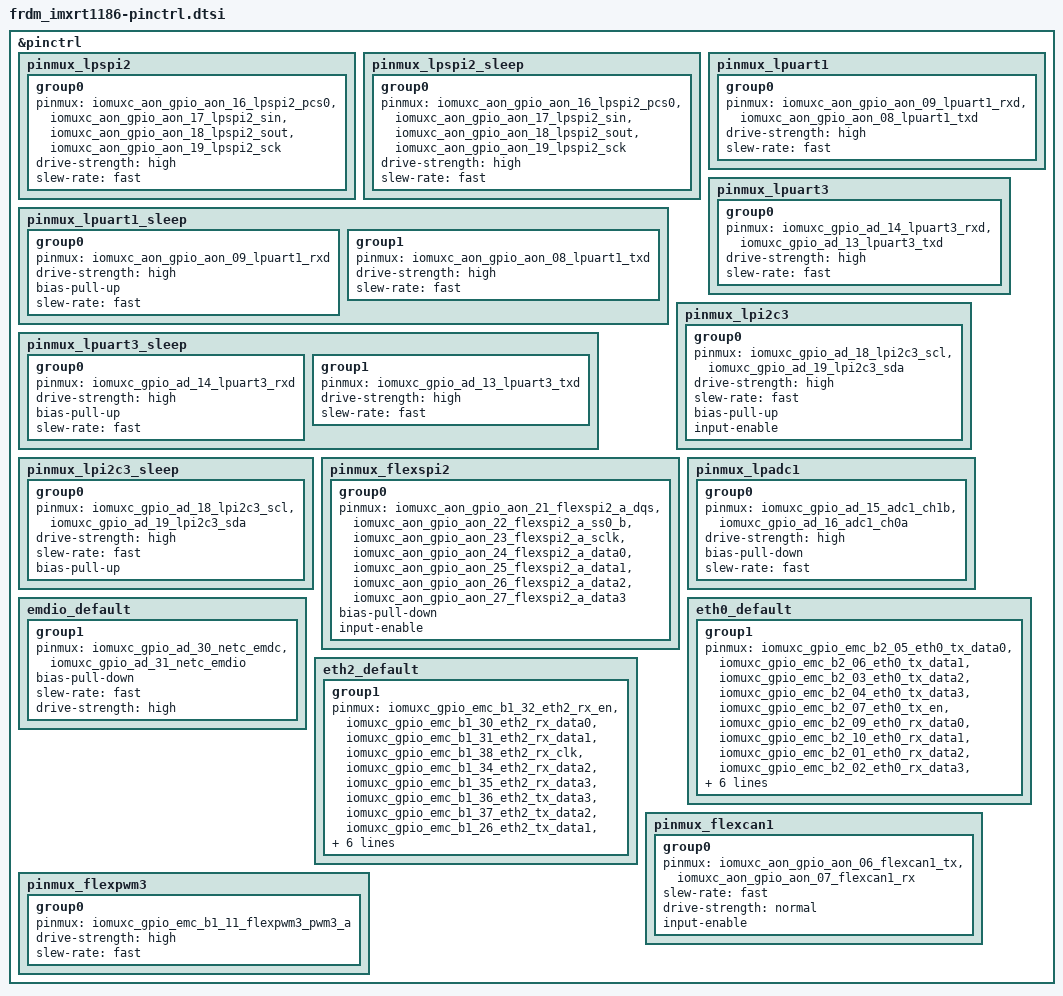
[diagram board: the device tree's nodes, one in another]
/*
 * Copyright 2026 NXP
 * SPDX-License-Identifier: Apache-2.0
 *
 */

#include <nxp/nxp_imx/rt/mimxrt1186cvj8c-pinctrl.dtsi>

&pinctrl {
	pinmux_lpspi2: pinmux_lpspi2 {
		group0 {
			pinmux = <&iomuxc_aon_gpio_aon_16_lpspi2_pcs0>,
				 <&iomuxc_aon_gpio_aon_17_lpspi2_sin>,
				 <&iomuxc_aon_gpio_aon_18_lpspi2_sout>,
				 <&iomuxc_aon_gpio_aon_19_lpspi2_sck>;
			drive-strength = "high";
			slew-rate = "fast";
		};
	};

	pinmux_lpspi2_sleep: pinmux_lpspi2_sleep {
		group0 {
			pinmux = <&iomuxc_aon_gpio_aon_16_lpspi2_pcs0>,
				 <&iomuxc_aon_gpio_aon_17_lpspi2_sin>,
				 <&iomuxc_aon_gpio_aon_18_lpspi2_sout>,
				 <&iomuxc_aon_gpio_aon_19_lpspi2_sck>;
			drive-strength = "high";
			slew-rate = "fast";
		};
	};

	pinmux_lpuart1: pinmux_lpuart1 {
		group0 {
			pinmux = <&iomuxc_aon_gpio_aon_09_lpuart1_rxd>,
				 <&iomuxc_aon_gpio_aon_08_lpuart1_txd>;
			drive-strength = "high";
			slew-rate = "fast";
		};
	};

	pinmux_lpuart1_sleep: pinmux_lpuart1_sleep {
		group0 {
			pinmux = <&iomuxc_aon_gpio_aon_09_lpuart1_rxd>;
			drive-strength = "high";
			bias-pull-up;
			slew-rate = "fast";
		};

		group1 {
			pinmux = <&iomuxc_aon_gpio_aon_08_lpuart1_txd>;
			drive-strength = "high";
			slew-rate = "fast";
		};
	};

	pinmux_lpuart3: pinmux_lpuart3 {
		group0 {
			pinmux = <&iomuxc_gpio_ad_14_lpuart3_rxd>,
				 <&iomuxc_gpio_ad_13_lpuart3_txd>;
			drive-strength = "high";
			slew-rate = "fast";
		};
	};

	pinmux_lpuart3_sleep: pinmux_lpuart3_sleep {
		group0 {
			pinmux = <&iomuxc_gpio_ad_14_lpuart3_rxd>;
			drive-strength = "high";
			bias-pull-up;
			slew-rate = "fast";
		};

		group1 {
			pinmux = <&iomuxc_gpio_ad_13_lpuart3_txd>;
			drive-strength = "high";
			slew-rate = "fast";
		};
	};

	pinmux_lpi2c3: pinmux_lpi2c3 {
		group0 {
			pinmux = <&iomuxc_gpio_ad_18_lpi2c3_scl>,
				 <&iomuxc_gpio_ad_19_lpi2c3_sda>;
			drive-strength = "high";
			slew-rate = "fast";
			bias-pull-up;
			input-enable;
		};
	};

	pinmux_lpi2c3_sleep: pinmux_lpi2c3_sleep {
		group0 {
			pinmux = <&iomuxc_gpio_ad_18_lpi2c3_scl>,
				 <&iomuxc_gpio_ad_19_lpi2c3_sda>;
			drive-strength = "high";
			slew-rate = "fast";
			bias-pull-up;
		};
	};

	/* QSPI Flash on FlexSPI2 - GPIO_AON_22/23/24/25/26/27 */
	pinmux_flexspi2: pinmux_flexspi2 {
		group0 {
			pinmux = <&iomuxc_aon_gpio_aon_21_flexspi2_a_dqs>,
				 <&iomuxc_aon_gpio_aon_22_flexspi2_a_ss0_b>,
				 <&iomuxc_aon_gpio_aon_23_flexspi2_a_sclk>,
				 <&iomuxc_aon_gpio_aon_24_flexspi2_a_data0>,
				 <&iomuxc_aon_gpio_aon_25_flexspi2_a_data1>,
				 <&iomuxc_aon_gpio_aon_26_flexspi2_a_data2>,
				 <&iomuxc_aon_gpio_aon_27_flexspi2_a_data3>;
			bias-pull-down;
			input-enable;
		};
	};

	pinmux_lpadc1: pinmux_lpadc1 {
		group0 {
			pinmux = <&iomuxc_gpio_ad_15_adc1_ch1b>,
				 <&iomuxc_gpio_ad_16_adc1_ch0a>;
			drive-strength = "high";
			bias-pull-down;
			slew-rate = "fast";
		};
	};

	emdio_default: emdio_default {
		group1 {
			pinmux = <&iomuxc_gpio_ad_30_netc_emdc>,
				 <&iomuxc_gpio_ad_31_netc_emdio>;
			bias-pull-down;
			slew-rate = "fast";
			drive-strength = "high";
		};
	};

	eth0_default: eth0_default {
		group1 {
			pinmux = <&iomuxc_gpio_emc_b2_05_eth0_tx_data0>,
				 <&iomuxc_gpio_emc_b2_06_eth0_tx_data1>,
				 <&iomuxc_gpio_emc_b2_03_eth0_tx_data2>,
				 <&iomuxc_gpio_emc_b2_04_eth0_tx_data3>,
				 <&iomuxc_gpio_emc_b2_07_eth0_tx_en>,
				 <&iomuxc_gpio_emc_b2_09_eth0_rx_data0>,
				 <&iomuxc_gpio_emc_b2_10_eth0_rx_data1>,
				 <&iomuxc_gpio_emc_b2_01_eth0_rx_data2>,
				 <&iomuxc_gpio_emc_b2_02_eth0_rx_data3>,
				 <&iomuxc_gpio_emc_b2_11_eth0_rx_en>,
				 <&iomuxc_gpio_emc_b2_08_eth0_tx_clk>,
				 <&iomuxc_gpio_emc_b2_00_eth0_rx_clk>;
			bias-pull-down;
			slew-rate = "fast";
			drive-strength = "high";
		};
	};

	eth2_default: eth2_default {
		group1 {
			pinmux = <&iomuxc_gpio_emc_b1_32_eth2_rx_en>,
				 <&iomuxc_gpio_emc_b1_30_eth2_rx_data0>,
				 <&iomuxc_gpio_emc_b1_31_eth2_rx_data1>,
				 <&iomuxc_gpio_emc_b1_38_eth2_rx_clk>,
				 <&iomuxc_gpio_emc_b1_34_eth2_rx_data2>,
				 <&iomuxc_gpio_emc_b1_35_eth2_rx_data3>,
				 <&iomuxc_gpio_emc_b1_36_eth2_tx_data3>,
				 <&iomuxc_gpio_emc_b1_37_eth2_tx_data2>,
				 <&iomuxc_gpio_emc_b1_26_eth2_tx_data1>,
				 <&iomuxc_gpio_emc_b1_27_eth2_tx_data0>,
				 <&iomuxc_gpio_emc_b1_28_eth2_tx_en>,
				 <&iomuxc_gpio_emc_b1_29_eth2_tx_clk>;
			bias-pull-down;
			slew-rate = "fast";
			drive-strength = "high";
		};
	};

	pinmux_flexcan1: pinmux_flexcan1 {
		group0 {
			pinmux = <&iomuxc_aon_gpio_aon_06_flexcan1_tx>,
				 <&iomuxc_aon_gpio_aon_07_flexcan1_rx>;
			slew-rate = "fast";
			drive-strength = "normal";
			input-enable;
		};
	};

	pinmux_flexpwm3: pinmux_flexpwm3 {
		group0 {
			pinmux = <&iomuxc_gpio_emc_b1_11_flexpwm3_pwm3_a>;
			drive-strength = "high";
			slew-rate = "fast";
		};
	};
};
